VERSION "0.1"

NS_ :

BS_: 1000000

BU_: PC X

BO_ 2147549442 Reboot: 0 Vector__XXX

BO_ 2147549698 SoftReset: 0 Vector__XXX

BO_ 2147549954 WriteToFlash: 0 Vector__XXX

BO_ 2147550210 ClearStatus: 0 Vector__XXX

BO_ 2147614978 SetDeviceId: 4 Vector__XXX
    SG_ id : 0|32@1+ (1,0) [0|0] "" Vector__XXX

BO_ 2147615234 SetCanBitrate: 1 Vector__XXX
    SG_ can_bitrate : 0|8@1+ (1,0) [0|0] "" Vector__XXX

BO_ 2147615490 SetStatusRate: 1 Vector__XXX
    SG_ status_rate : 0|8@1+ (1,0) [0|0] "" Vector__XXX

BO_ 2147680514 GetProductInfo: 0 Vector__XXX

BO_ 2147680770 GetConfig: 0 Vector__XXX

BO_ 2147746050 Ack: 4 Vector__XXX
    SG_ ident : 0|32@1+ (1,0) [0|0] "" Vector__XXX

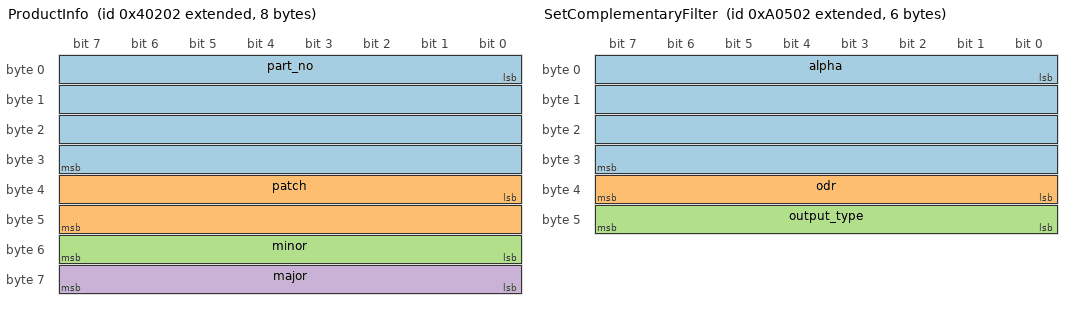
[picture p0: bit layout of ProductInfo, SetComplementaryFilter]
BO_ 2147746306 ProductInfo: 8 Vector__XXX
    SG_ part_no : 0|32@1+ (1,0) [0|0] "" Vector__XXX
    SG_ patch : 32|16@1+ (1,0) [0|0] "" Vector__XXX
    SG_ minor : 48|8@1+ (1,0) [0|0] "" Vector__XXX
    SG_ major : 56|8@1+ (1,0) [0|0] "" Vector__XXX

BO_ 2147746562 StatusRate: 1 Vector__XXX
    SG_ status_rate : 0|8@1+ (1,0) [0|0] "" Vector__XXX

BO_ 2147942402 Status: 1 Vector__XXX
    SG_ status : 0|8@1+ (1,0) [0|0] "" Vector__XXX

BO_ 2148073730 DoGyroCalibration: 0 Vector__XXX

BO_ 2148139266 SetAccelFilter: 2 Vector__XXX
    SG_ odr_div : 0|8@1+ (1,0) [0|0] "" Vector__XXX
    SG_ lp_div : 8|8@1+ (1,0) [0|0] "" Vector__XXX

BO_ 2148139522 SetGyroFilter: 2 Vector__XXX
    SG_ odr_div : 0|8@1+ (1,0) [0|0] "" Vector__XXX
    SG_ lp_div : 8|8@1+ (1,0) [0|0] "" Vector__XXX

BO_ 2148139778 SetAccelResolution: 1 Vector__XXX
    SG_ full_scale : 0|8@1+ (1,0) [0|0] "" Vector__XXX

BO_ 2148140034 SetGyroResolution: 1 Vector__XXX
    SG_ full_scale : 0|8@1+ (1,0) [0|0] "" Vector__XXX

BO_ 2148140290 SetComplementaryFilter: 6 Vector__XXX
    SG_ alpha : 0|32@1+ (1,0) [0|0] "" Vector__XXX
    SG_ odr : 32|8@1+ (1,0) [0|0] "" Vector__XXX
    SG_ output_type : 40|8@1+ (1,0) [0|0] "" Vector__XXX

BO_ 2148140546 SetDeviceOrientation: 8 Vector__XXX
    SG_ pitch : 0|32@1+ (1,0) [0|0] "degrees" Vector__XXX
    SG_ roll : 32|32@1+ (1,0) [0|0] "degrees" Vector__XXX

BO_ 2148204802 GetScalingFactors: 0 Vector__XXX

BO_ 2148205058 GetSensorFreqFine: 0 Vector__XXX

BO_ 2148270338 AccelFilter: 2 Vector__XXX
    SG_ odr_div : 0|8@1+ (1,0) [0|0] "" Vector__XXX
    SG_ lp_div : 8|8@1+ (1,0) [0|0] "" Vector__XXX

BO_ 2148270594 GyroFilter: 2 Vector__XXX
    SG_ odr_div : 0|8@1+ (1,0) [0|0] "" Vector__XXX
    SG_ lp_div : 8|8@1+ (1,0) [0|0] "" Vector__XXX

BO_ 2148270850 AccelResolution: 1 Vector__XXX
    SG_ full_scale : 0|8@1+ (1,0) [0|0] "" Vector__XXX

BO_ 2148271106 GyroResolution: 1 Vector__XXX
    SG_ full_scale : 0|8@1+ (1,0) [0|0] "" Vector__XXX

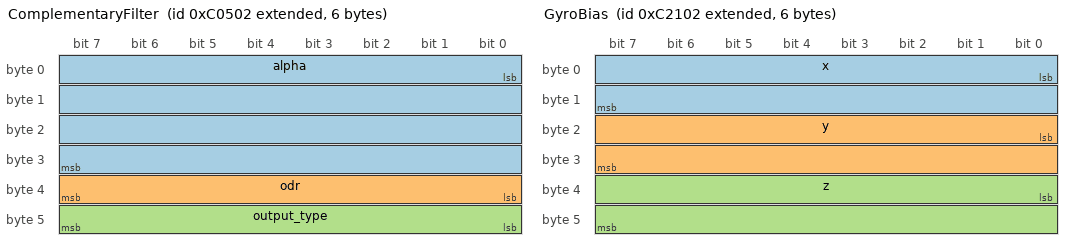
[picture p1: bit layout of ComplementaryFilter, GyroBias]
BO_ 2148271362 ComplementaryFilter: 6 Vector__XXX
    SG_ alpha : 0|32@1+ (1,0) [0|0] "" Vector__XXX
    SG_ odr : 32|8@1+ (1,0) [0|0] "" Vector__XXX
    SG_ output_type : 40|8@1+ (1,0) [0|0] "" Vector__XXX

BO_ 2148271618 DeviceOrientation: 8 Vector__XXX
    SG_ pitch : 0|32@1+ (1,0) [0|0] "degrees" Vector__XXX
    SG_ roll : 32|32@1+ (1,0) [0|0] "degrees" Vector__XXX

BO_ 2148274434 ScalingFactors: 8 Vector__XXX
    SG_ accel_scale : 0|32@1+ (1,0) [0|0] "" Vector__XXX
    SG_ gyro_scale : 32|32@1+ (1,0) [0|0] "" Vector__XXX

BO_ 2148274690 SensorFreqFine: 4 Vector__XXX
    SG_ fine : 0|32@1+ (1,0) [0|0] "" Vector__XXX

BO_ 2148278530 GyroBias: 6 Vector__XXX
    SG_ x : 0|16@1- (1,0) [0|0] "" Vector__XXX
    SG_ y : 16|16@1- (1,0) [0|0] "" Vector__XXX
    SG_ z : 32|16@1- (1,0) [0|0] "" Vector__XXX

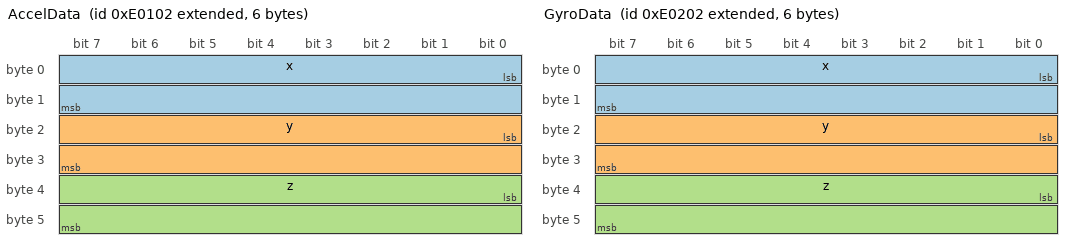
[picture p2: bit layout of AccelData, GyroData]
BO_ 2148401410 AccelData: 6 Vector__XXX
    SG_ x : 0|16@1- (1,0) [0|0] "" Vector__XXX
    SG_ y : 16|16@1- (1,0) [0|0] "" Vector__XXX
    SG_ z : 32|16@1- (1,0) [0|0] "" Vector__XXX

BO_ 2148401666 GyroData: 6 Vector__XXX
    SG_ x : 0|16@1- (1,0) [0|0] "" Vector__XXX
    SG_ y : 16|16@1- (1,0) [0|0] "" Vector__XXX
    SG_ z : 32|16@1- (1,0) [0|0] "" Vector__XXX

BO_ 2148401922 TiltAngles: 8 Vector__XXX
    SG_ pitch : 0|32@1+ (1,0) [0|0] "degrees" Vector__XXX
    SG_ roll : 32|32@1+ (1,0) [0|0] "degrees" Vector__XXX

BO_ 2148402178 QuatWX: 8 Vector__XXX
    SG_ w : 0|32@1+ (1,0) [0|0] "" Vector__XXX
    SG_ x : 32|32@1+ (1,0) [0|0] "" Vector__XXX

BO_ 2148402434 QuatYZ: 8 Vector__XXX
    SG_ y : 0|32@1+ (1,0) [0|0] "" Vector__XXX
    SG_ z : 32|32@1+ (1,0) [0|0] "" Vector__XXX

BO_ 2148531714 DeviceId: 1 Vector__XXX
    SG_ id : 0|8@1+ (1,0) [0|0] "" Vector__XXX

BO_ 2148531970 CanSpeed: 1 Vector__XXX
    SG_ can_bitrate : 0|8@1+ (1,0) [0|0] "" Vector__XXX

BA_DEF_DEF_ "BusType" "CAN";

SIG_VALTYPE_ 2148274434 accel_scale : 1;
SIG_VALTYPE_ 2148274434 gyro_scale : 1;
SIG_VALTYPE_ 2148140290 alpha : 1;
SIG_VALTYPE_ 2148140546 pitch : 1;
SIG_VALTYPE_ 2148140546 roll : 1;
SIG_VALTYPE_ 2148271362 alpha : 1;
SIG_VALTYPE_ 2148271618 pitch : 1;
SIG_VALTYPE_ 2148271618 roll : 1;
SIG_VALTYPE_ 2148401922 pitch : 1;
SIG_VALTYPE_ 2148401922 roll : 1;
SIG_VALTYPE_ 2148402178 w : 1;
SIG_VALTYPE_ 2148402178 x : 1;
SIG_VALTYPE_ 2148402434 y : 1;
SIG_VALTYPE_ 2148402434 z : 1;
